# D1H.pdf register map
Vendor: Allwinner; Series: D1H.pdf; File version: 0.1
CPU: XuanTie C906 RISC-V CPU 0, little endian, MPU, FPU, double-precision FPU, 0 interrupt priority bits
Registers are 32-bit, read-write, reset 0x0 unless marked. A register's access mark holds for its fields unless they carry their own. Offsets are from the block's base; [hi:lo] are bit positions; lines under a group give offsets from that group.

## USB1 (part 1 of 2)
Base 0x04200000
0x00 HCI CONTROLLER AND PHY INTERFACE REGISTER group
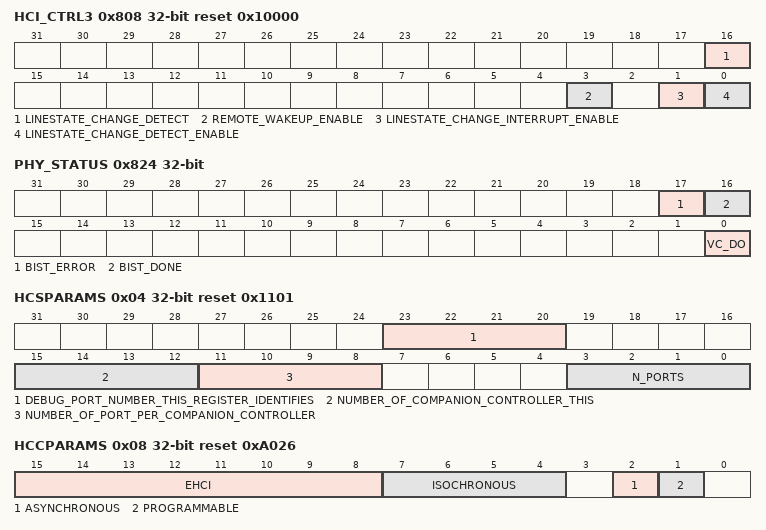
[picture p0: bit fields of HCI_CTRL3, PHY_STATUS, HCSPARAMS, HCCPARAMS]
  0x808 HCI_CTRL3 reset 0x10000 — HCI Control Register
    [16] LINESTATE_CHANGE_DETECT write-1-clears — Linestate Change Detect 0: Linestate change not dected 1: Linestate change dected Write ‘1’ to clear.
      0=Linestate_change_not_dected; 1=Linestate change dected Write ‘1’ to clear
    [3] REMOTE_WAKEUP_ENABLE — Remote Wakeup Enable 1: Enable 0: Disable
      1=Enable; 0=Disable
    [1] LINESTATE_CHANGE_INTERRUPT_ENABLE — Linestate Change Interrupt Enable 1: Enable 0: Disable
      1=Enable; 0=Disable
    [0] LINESTATE_CHANGE_DETECT_ENABLE — Linestate Change Detect Enable 1: Enable 0: Disable
      1=Enable; 0=Disable
  0x824 PHY_STATUS
    [17] BIST_ERROR ro, [16] BIST_DONE ro, [0] VC_DO ro
0x00 CAPLENGTH reset 0x10
  [7:0] CAPLENGTH ro — The value in these bits indicates an offset to add to register base to find the beginning of the Operational Register Space.
0x02 HCIVERSION reset 0x100
  [15:0] HCIVERSION ro — This is a 16-bit register containing a BCD encoding of the EHCI revision number supported by this host controller. The most significant byte of this register represents a major revision and the least significant byte is the minor revision.
0x04 HCSPARAMS reset 0x1101
  [23:20] DEBUG_PORT_NUMBER_THIS_REGISTER_IDENTIFIES ro — Debug Port Number This register identifies which of the host controller ports is the debug port. The value is the port number (one based) of the debug port. This field will always be ‘0’.
  [15:12] NUMBER_OF_COMPANION_CONTROLLER_THIS ro — Number of Companion Controller (N_CC) This field indicates the number of companion controllers associated with this USB2.0 host controller. A zero in this field indicates there are no companion host controllers. And a value larger than zero in this field indicates there are companion USB1.1 host controller(s). This field will always be ‘0’.
  [11:8] NUMBER_OF_PORT_PER_COMPANION_CONTROLLER ro — Number of Port per Companion Controller (N_PCC) This field indicates the number of ports supported per companion host controller host controller. It is used to indicate the port routing configuration to system software. This field will always fix with ‘0’.
  [3:0] N_PORTS ro — This field specifies the number of physical downstream ports implemented on this host controller. The value of this field determines how many port registers are addressable in the Operational Register Space. Valid values are in the range of 0x1 to 0x0f. This field is always 1.
0x08 HCCPARAMS reset 0xA026
  [15:8] EHCI ro — Extended Capabilities Pointer (EECP) This optional field indicates the existence of a capabilities list. A value of 00b indicates no extended capabilities are implemented. A non-zero value in this register indicates the offset in PCI configuration space of the first EHCI extended capabiliby. The pointer value must be 40h or greater if implemented to maintain to consistency of the PCI header defined for this calss of device. The value of this field is always ‘00b’.
  [7:4] ISOCHRONOUS ro — Isochronous Scheduling Threshold This field indicates, relative to the current position of the executing host controller, where software can reliably update the isochronous schedule. When bit[7] is zero, the value of the least significant 3 bits indicates the number of micro-frames a host controller can hold a set of isochronous data structures(one or more) before flushing the state. When bit[7] is a one, then host software assumes the host controller may cache an isochronous data structure for an entire frame.
  [2] ASYNCHRONOUS ro — Asynchronous Schedule Park Capability If this bit is set to a one, then the host controller supports the park feature for high-speed queue heads in the Asynchronous Schedule. The feature can be disabled or enabled and set to a specific level by using the Asynchronous Schedule Park Mode Enable and Asynchronous Schedule Park Mode Count fields in the USBCMD register.
  [1] PROGRAMMABLE ro — Programmable Frame List Flag If this bit is set to a zero, then system software must use a frame list length of 1024 elements with this host controller. The USBCMD register Frame List Size field is a read-only register and should be set to zero. If set to 1, then system software can specify and use the frame list in the USBCMD register Frame List Size field to cofigure the host controller. The frame list must always aligned on a 4K page boundary. This requirement ensures that the frame list is always physically contiguous.
0x0C HCSP_PORTROUTE
  [31:0] HCSP-PORTROUTE ro — This optional field is valid only if Port Routing Rules field in HCSPARAMS register is set to a one. This field is used to allow a host controller implementation to explicitly describe to which companion host controller each implemented port is mapped. This field is a 15-element nibble array (each 4 bit is one array element). Each array location corresponds one-to-one with a physical port provided by the host controller (e.g. PORTROUTE [0] corresponds to the first PORTSC port, PORTROUTE [1] to the second PORTSC port, etc.). The value of each element indicates to which the companion host controllers this port is routed. Only the first N_PORTS elements have valid information. A value of zero indicates that the port is routed to the lowest numbered function companion host controller. A value of one indicates that the port is routed to the next lowest numbered function companion host controller, and so on.
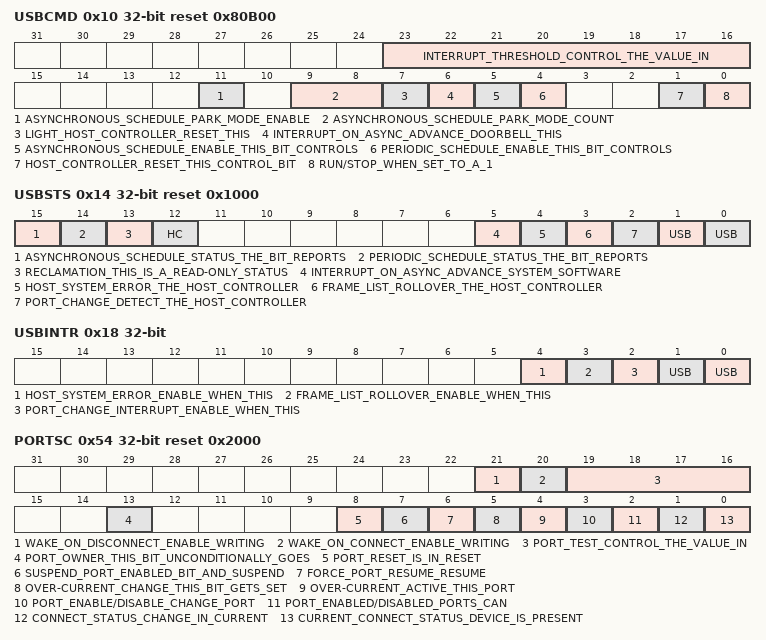
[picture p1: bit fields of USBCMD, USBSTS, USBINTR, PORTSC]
0x10 USBCMD reset 0x80B00
  [23:16] INTERRUPT_THRESHOLD_CONTROL_THE_VALUE_IN — Interrupt Threshold Control The value in this field is used by system software to select the maximum rate at which the host controller will issue interrupts. The only valid values are defined below: Value Minimum Interrupt Interval 0x00 Reserved 0x01 1 micro-frame 0x02 2 micro-frame 0x04 4 micro-frame 0x08 8 micro-frame(default, equates to 1 ms) 0x10 16 micro-frame(2ms) 0x20 32 micro-frame(4ms) 0x40 64 micro-frame(8ms) Any other value in this register yields undefined results. The default value in this field is 0x08 . Software modifications to this bit while HC Halted bit is equal to zero results in undefined behavior.
  [11] ASYNCHRONOUS_SCHEDULE_PARK_MODE_ENABLE ro — Asynchronous Schedule Park Mode Enable (OPTIONAL) If the Asynchronous Park Capability bit in the HCCPARAMS register is a one, then this bit defaults to a 1 and is R/W. Otherwise the bit must be a zero and is Read Only. Software uses this bit to enable or disable Park mode. When this bit is one, Park mode is enabled. When this bit is zero, Park mode is disabled.
  [9:8] ASYNCHRONOUS_SCHEDULE_PARK_MODE_COUNT ro — Asynchronous Schedule Park Mode Count (OPTIONAL) Asynchronous Park Capability bit in the HCCPARAMS register is a one, then this field defaults to 0x3 and is W/R. Otherwise it defaults to zero and is R. It contains a count of the number of successive transactions the host controller is allowed to execute from a high-speed queue head on the Asynchronous schedule before continuing traversal of the Asynchronous schedule. Valid value are 0x1 to 0x3.Software must not write a zero to this bit when Park Mode Enable is a one as it will result in undefined behavior.
  [7] LIGHT_HOST_CONTROLLER_RESET_THIS — Light Host Controller Reset (OPTIONAL) This control bit is not required. If implemented, it allows the driver to reset the EHCI controller without affecting the state of the ports or relationship to the companion host controllers. For example, the PORSTC registers should not be reset to their default values and the CF bit setting should not go to zero (retaining port ownership relationships). A host software read of this bit as zero indicates the Light Host Controller Reset has completed and it si safe for software to re- initialize the host controller. A host software read of this bit as a one indicates the Light Host
  [6] INTERRUPT_ON_ASYNC_ADVANCE_DOORBELL_THIS — Interrupt on Async Advance Doorbell This bit is used as a doorbell by software to tell the host controller to issue an interrupt the next time it advances asynchronous schedule. Software must write a 1 to this bit to ring the doorbell. When the host controller has evicted all appropriate cached schedule state, it sets the Interrupt on Async Advance status bit in the USBSTS. if the Interrupt on Async Advance Enable bit in the USBINTR register is a one then the host controller will assert an interrupt at the next interrupt threshold. The host controller sets this bit to a zero after it has set the Interrupt on Async Advance status bit in the USBSTS register to a one. Software should not write a one to this bit when the asynchronous schedule is disabled. Doing so will yield undefined results.
  [5] ASYNCHRONOUS_SCHEDULE_ENABLE_THIS_BIT_CONTROLS — Asynchronous Schedule Enable This bit controls whether the host controller skips processing the Asynchronous Schedule. Values mean: Bit Value Meaning 0 Do not process the Asynchronous Schedule. 1 Use the ASYNLISTADDR register to access the Asynchronous Schedule. The default value of this field is ‘0b’.
  [4] PERIODIC_SCHEDULE_ENABLE_THIS_BIT_CONTROLS — Periodic Schedule Enable This bit controls whether the host controller skips processing the Periodic Schedule. Values mean: Bit Value Meaning 0 Do not process the Periodic Schedule. 1 Use the PERIODICLISTBASE register to access the Periodic Schedule. The default value of this field is ‘0b’.
  [1] HOST_CONTROLLER_RESET_THIS_CONTROL_BIT — Host Controller Reset This control bit is used by software to reset the host controller. The effects of this on Root Hub registers are similar to a Chip Hardware Reset. When software writes a one to this bit, the Host Controller resets its internal pipelines, timers, counters, state machines, etc. to their initial value. Any transaction currently in progress on USB is immediately terminated. A USB reset is not driven on downstream ports. All operational registers, including port registers and port state machines are set to their initial values. Port ownership reverts to the companion host controller(s). Software must reinitialize the host controller as described in Section 4.1 of the CHEI Specification in order to return the host controller to an operational state. This bit is set to zero by the Host Controller when the reset process is complete. Software cannot terminate the reset process early by writing a zero to this register. Software should not set this bit to a one when the HC Halted bit in the USBSTS register is a zero. Attempting to reset an actively running host controller will result in undefined behavior.
  [0] RUN/STOP_WHEN_SET_TO_A_1 — Run/Stop When set to a 1, the Host Controller proceeds with execution of the schedule. When set to 0, the Host Controller completes the current and any actively pipelined transactions on the USB and then halts. The Host Controller must halt within 16 micro-frames after software clears this bit. The HC Halted bit indicates when the Host Controller has finished its pending pipelined transactions and has entered the stopped state. Software must not write a one to this field unless the Host Controller is in the Halt State. The default value is 0x0.
0x14 USBSTS reset 0x1000
  [15] ASYNCHRONOUS_SCHEDULE_STATUS_THE_BIT_REPORTS ro — Asynchronous Schedule Status The bit reports the current real status of Asynchronous Schedule. If this bit is a zero then the status of the Asynchronous Schedule is disabled. If this bit is a one then the status of the Asynchronous Schedule is enabled. The Host Controller is not required to immediately disable or enable the Asynchronous Schedule when software transitions the Asynchronous Schedule Enable bit in the USBCMD register. When this bit and the Asynchronous Schedule Enable bit are the same value, the Asynchronous Schedule is either enabled (1) or disabled (0).
  [14] PERIODIC_SCHEDULE_STATUS_THE_BIT_REPORTS ro — Periodic Schedule Status The bit reports the current real status of the Periodic Schedule. If this bit is a zero then the status of the Periodic Schedule is disabled. If this bit is a one then the status of the Periodic Schedule is enabled. The Host Controller is not required to disable or enable the Periodic Schedule when software transitions the bit in the USBCMD register. When this bit and the bit are the same value, the Periodic Schedule is either enabled (1) or disabled (0).
  [13] RECLAMATION_THIS_IS_A_READ-ONLY_STATUS ro — Reclamation This is a read-only status bit, which is used to detect an empty asynchronous schedule.
  [12] HC ro — Halted This bit is a zero whenever the Run/Stop bit is a one. The Host Controller Sets this bit to one after it has stopped executing as a result of the Run/Stop bit being set to 0, either by software or by the Host Controller Hardware (e.g. internal error). The default value is ‘1’.
  [5] INTERRUPT_ON_ASYNC_ADVANCE_SYSTEM_SOFTWARE write-clears — Interrupt on Async Advance System software can force the host controller to issue an interrupt the next time the host controller advances the asynchronous schedule by writing a one to the Interrupt on Async Advance Doorbell bit in the USBCMD register. This status bit indicates the assertion of that interrupt source.
  [4] HOST_SYSTEM_ERROR_THE_HOST_CONTROLLER write-clears — Host System Error The Host Controller set this bit to 1 when a serious error occurs during a host system access involving the Host Controller module. When this error occurs, the Host Controller clears the Run/Stop bit in the Command register to prevent further execution of the scheduled TDs.
  [3] FRAME_LIST_ROLLOVER_THE_HOST_CONTROLLER write-clears — Frame List Rollover The Host Controller sets this bit to a one when the Frame List Index rolls over from its maximum value to zero. The exact value at which the rollover occurs depends on the frame list size. For example, if the frame list size is 1024, the Frame Index Register rolls over every time FRINDEX [13] toggles. Similarly, if the size is 512, the Host Controller sets this bit to a one every time FRINDEX [12] toggles.
  [2] PORT_CHANGE_DETECT_THE_HOST_CONTROLLER write-clears — Port Change Detect The Host Controller sets this bit to a one when any port for which the Port Owner bit is set to zero has a change bit transition from a zero to a one or a Force Port Resume bit transition from a zero to a one as a result of a J-K transition detected on a suspended port. This bit will also be set as a result of the Connect Status Chang being set to a one after system software has relinquished ownership of a connected port by writing a one to a port’s Port Owner bit.
  [1] USB write-clears — Error Interrupt(USBERRINT) The Host Controller sets this bit to 1 when completion of USB transaction results in an error condition(e.g. error counter underflow).If the TD on which the error interrupt occurred also had its IOC bit set, both. This bit and USBINT bit are set.
  [0] USB write-clears — Interrupt(USBINT) The Host Controller sets this bit to a one on the completion of a USB transaction, which results in the retirement of a Transfer Descriptor that had its IOC bit set. The Host Controller also sets this bit to 1 when a short packet is detected (actual number of bytes received was less than the expected number of bytes)
0x18 USBINTR
  [4] HOST_SYSTEM_ERROR_ENABLE_WHEN_THIS — Host System Error Enable When this bit is 1, and the Host System Error Status bit in the USBSTS register is 1, the host controller will issue an interrupt. The interrupt is acknowledged by software clearing the Host System Error bit.
  [3] FRAME_LIST_ROLLOVER_ENABLE_WHEN_THIS — Frame List Rollover Enable When this bit is 1, and the Frame List Rollover bit in the USBSTS register is 1, the host controller will issue an interrupt. The interrupt is acknowledged by software clearing the Frame List Rollover bit.
  [2] PORT_CHANGE_INTERRUPT_ENABLE_WHEN_THIS — Port Change Interrupt Enable When this bit is 1, and the Port Chang Detect bit in the USBSTS register is 1, the host controller will issue an interrupt. The interrupt is acknowledged by software clearing the Port Chang Detect bit.
  [1] USB — Error Interrupt Enable When this bit is 1, and the USBERRINT bit in the USBSTS register is 1,the host controller will issue an interrupt at the next interrupt threshold. The interrupt is acknowledged by software clearing the USBERRINT bit.
  [0] USB — Interrupt Enable When this bit is 1, and the USBINT bit in the USBSTS register is 1,the host controller will issue an interrupt at the next interrupt threshold. The interrupt is acknowledged by software clearing the USBINT bit
0x1C FRINDEX
  [13:0] FRAME — Frame Index The value in this register increment at the end of each time frame (e.g. micro-frame). Bits[N:3] are used for the Frame List current index. It means that each location of the frame list is accessed 8 times (frames or Micro-frames) before moving to the next index. The following illustrates values of N based on the value of the Frame List Size field in the USBCMD register. USBCMD[Frame List Size] Number Elements N 00b 1024 12 01b 512 11 10b 256 10 11b Reserved This register must be written as a DWord. Byte writes produce undefined results.
0x24 PERIODICLISTBASE
  [31:12] BASE — Base Address These bits correspond to memory address signals [31:12], respectively. This register contains the beginning address of the Periodic Frame List in the system memory. System software loads this register prior to starting the schedule execution by the Host Controller. The memory structure referenced by this physical memory pointer is assumed to be 4 Kbyte aligned. The contents of this register are combined with the Frame Index Register (FRINDEX) to enable the Host Controller to step through the Periodic Frame List in sequence.
0x28 ASYNCLISTADDR
  [31:5] LINK — Link Pointer (LP) This field contains the address of the next asynchronous queue head to be executed. These bits correspond to memory address signals [31:5], respectively.
0x50 CONFIGFLAG
  [0] CONFIGURE — Configure Flag (CF) Host software sets this bit as the last action in its process of configuring the Host Controller. This bit controls the default port- routing control logic as follow: Value Meaning 0 Port routing control logic default-routs each port to an implementation dependent classic host controller. 1 Port routing control logic default-routs all ports to this host controller. The default value of this field is ‘0’. This register is not used in the normal implementation.
0x54 PORTSC reset 0x2000
  [21] WAKE_ON_DISCONNECT_ENABLE_WRITING — Wake on Disconnect Enable (WKDSCNNT_E) Writing this bit to a one enables the port to be sensitive to device disconnects as wake-up events. This field is zero if Port Power is zero. The default value in this field is ‘0’.
  [20] WAKE_ON_CONNECT_ENABLE_WRITING — Wake on Connect Enable (WKCNNT_E) Writing this bit to a one enable the port to be sensitive to device connects as wake-up events. This field is zero if Port Power is zero. The default value in this field is ‘0’.
  [19:16] PORT_TEST_CONTROL_THE_VALUE_IN — Port Test Control The value in this field specifies the test mode of the port. The encoding of the test mode bits are as follows: Bits Test Mode 0000b The port is NOT operating in a test mode. 0001b Test J_STATE 0010b Test K_STATE 0011b Test SE0_NAK 0100b Test Packet 0101b Test FORCE_ENABLE 0110b- 1111b Reserved The default value in this field is ‘0000b’.
  [13] PORT_OWNER_THIS_BIT_UNCONDITIONALLY_GOES — Port Owner This bit unconditionally goes to a 0b when the Configured bit in the CONFIGFLAG register makes a 0b to 1b transition. This bit unconditionally goes to 1b whenever the Configured bit is zero. System software uses this field to release ownership of the port to selected host controller (in the event that the attached device is not a high-speed device).Software writes a one to this bit when the attached device is not a high-speed device. A one in this bit means that a companion host controller owns and controls the port. Default Value = 1b.
  [8] PORT_RESET_IS_IN_RESET — Port Reset 1=Port is in Reset. 0=Port is not in Reset. Default value = 0. When software writes a one to this bit (from a zero), the bus reset sequence as defined in the USB Specification Revision 2.0 is started. Software writes a zero to this bit to terminate the bus reset sequence. Software must keep this bit at a one long enough to ensure the reset sequence, as specified in the USB Specification Revision 2.0, completes. Note that when software writes a zero to this bit there may be a delay before the bit status changes to a zero. The bit status will not read as a zero until after the reset has completed. If the port is in high-speed mode after reset is complete, the host controller will automatically enable this port (e.g. set the Port Enable bit to a one). A host controller must terminate the reset and stabilize the state of the port within 2 milliseconds of software transitioning this bit from a one to a zero. For example: if the port detects that the attached device is high-speed during reset, then the host controller must have the port in the enabled state with 2ms of software writing this bit to a zero. The HC Halted bit in the USBSTS register should be a zero before software attempts to use this bit. The host controller may hold Port Reset asserted to a one when the HC Halted bit is a one. This field is zero if Port Power is zero.
  [7] SUSPEND_PORT_ENABLED_BIT_AND_SUSPEND — Suspend Port Enabled Bit and Suspend bit of this register define the port states as follows: Bits[Port Enables, Suspend] Port State 0x Disable 10 Enable 11 Suspend When in suspend state, downstream propagation of data is blocked on this port, except for port reset. The blocking occurs at the end of the current transaction, if a transaction was in progress when this bit was written to 1. In the suspend state, the port is sensitive to resume detection. Not that the bit status does not change until the port is suspend and that there may be a delay in suspending a port if there is a transaction currently in progress on the USB. A write of zero to this bit is ignored by the host controller. The host controller will unconditionally set this bit to a zero when: ① Software sets the Force Port Resume bit to a zero(from a one). ② Software sets the Port Reset bit to a one(from a zero). If host software sets this bit to a one when the port is not enabled(i.e. Port enabled bit is a zero), the results are undefined. This field is zero if Port Power is zero. The default value in this field is ‘0’.
  [6] FORCE_PORT_RESUME_RESUME — Force Port Resume 1 = Resume detected/driven on port. 0 = No resume (K-state) detected/driven on port. Default value = 0. This functionality defined for manipulating this bit depends on the value of the Suspend bit. For example, if the port is not suspend and software transitions this bit to a one, then the effects on the bus are undefined. Software sets this bit to 1 to drive resume signaling. The Host Controller sets this bit to a 1 if a J-to-K transition is detected while the port is in the Suspend state. When this bit transitions to a one because a J-to-K transition is detected, the Port Change Detect bit in the USBSTS register is also set to a one. If software sets this bit to a one, the host controller must not set the Port Change Detect bit. Note that when the EHCI controller owns the port, the resume sequence follows the defined sequence documented in the USB Specification Revision 2.0. The resume signaling (Full-speed ‘K’) is driven on the port as long as this remains a one. Software must appropriately time the Resume and set this bit to a zero when the appropriate amount of time has elapsed. Writing a zero (from one) causes the port to return high-speed mode (forcing the bus below the port into a high-speed idle). This bit will remain a one until the port has switched to high-speed idle. The host controller must complete this transition within 2 milliseconds of software setting this bit to a zero. This field is zero if Port Power is zero.
  [5] OVER-CURRENT_CHANGE_THIS_BIT_GETS_SET write-clears — Over-current Change This bit gets set to a one when there is a change to Over-current Active. Software clears this bit by writing a one to this bit position.
  [4] OVER-CURRENT_ACTIVE_THIS_PORT ro — Over-current Active 0 = This port does not have an over-current condition 1 = This port currently has an over-current condition This bit will automatically transition from a one to a zero when the over current condition is removed. The default value of this bit is ‘0’.
  [3] PORT_ENABLE/DISABLE_CHANGE_PORT write-clears — Port Enable/Disable Change 1 = Port enabled/disabled status has changed 0 = No change For the root hub, this bit gets set to a one only when a port is disabled due to the appropriate conditions existing at the EOF2 point (See Chapter 11 of the USB Specification for the definition of a Port Error). Software clears this bit by writing a 1 to it. This field is zero if Port Power is zero.
  [2] PORT_ENABLED/DISABLED_PORTS_CAN — Port Enabled/Disabled 1=Enable 0=Disable Ports can only be enabled by the host controller as a part of the reset and enable. Software cannot enable a port by writing a one to this field. The host controller will only set this bit to a one when the reset sequence determines that the attached device is a high- speed device. Ports can be disabled by either a fault condition(disconnect event or other fault condition) or by host software. Note that the bit status does not change until the port state actually changes. There may be a delay in disabling or enabling a port due to other host controller and bus events. When the port is disabled, downstream propagation of data is blocked on this port except for reset. The default value of this field is ‘0’. This field is zero if Port Power is zero.
  [1] CONNECT_STATUS_CHANGE_IN_CURRENT write-clears — Connect Status Change 1=Change in Current Connect Status 0=No change Indicates a change has occurred in the current connect status of the port. The host controller sets this bit for all changes to the port device connect status, even if system software has not cleared an existing connect status change. For example, the insertion status changes twice before system software has cleared the changed condition, hub hardware will be “setting” an already-set bit. Software sets this bit to 0 by writing a 1 to it. This field is zero if Port Power is zero.
  [0] CURRENT_CONNECT_STATUS_DEVICE_IS_PRESENT ro — Current Connect Status Device is present on port when the value of this field is a one, and no device is present on port when the value of this field is a zero. This value reflects the current state of the port, and may not correspond directly to the event that caused the Connect Status Change(Bit 1) to be set. This field is zero if Port Power zero. This register is only reset by hardware or in response to a host controller reset.
